# CM41x_M0 register map
Vendor: Analog Devices; Series: CM41x_M0; File version: 1p0
CPU: CM0 r0p0, little endian, MPU, FPU, 4 interrupt priority bits
Registers are 32-bit, read-write, reset 0x0 unless marked. A register's access mark holds for its fields unless they carry their own. Offsets are from the block's base; [hi:lo] are bit positions; lines under a group give offsets from that group; {n}, {i} and the like mark numbered series.

## PORTB — The General-Purpose Input/Output Port
Base 0x40008000
Same registers: PORTC 0x40009000, PORTD 0x4000A000, PORTE 0x4000B000, PORTF 0x4000C000, PORTA 0x41003000
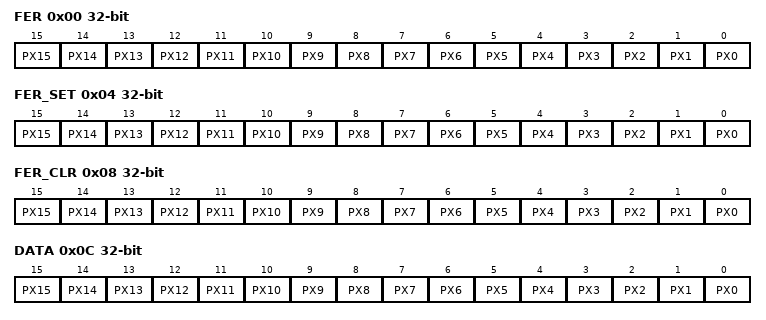
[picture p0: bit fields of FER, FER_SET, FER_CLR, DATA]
0x00 FER — Port x Function Enable Register
  [n] PX{n} (n=0..15) — Port x Bit {n} Mode
0x04 FER_SET — Port x Function Enable Set Register
  [n] PX{n} (n=0..15) — Port x Bit {n} Mode Set
0x08 FER_CLR — Port x Function Enable Clear Register
  [n] PX{n} (n=0..15) — Port x Bit {n} Mode Clear
0x0C DATA — Port x GPIO Data Register
  [n] PX{n} (n=0..15) — Port x Bit {n} Data
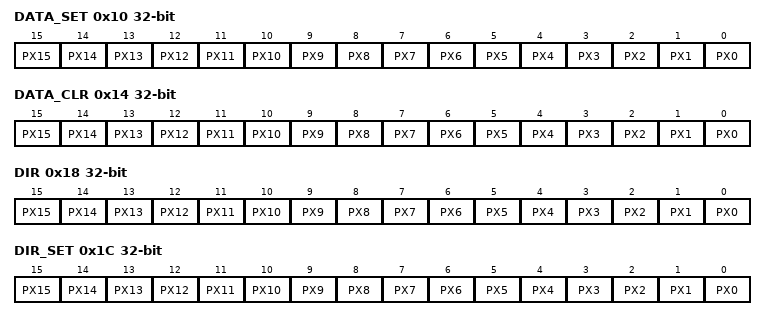
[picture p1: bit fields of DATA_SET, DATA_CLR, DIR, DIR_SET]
0x10 DATA_SET — Port x GPIO Data Set Register
  [n] PX{n} (n=0..15) — Port x Bit {n} Data Set
0x14 DATA_CLR — Port x GPIO Data Clear Register
  [n] PX{n} (n=0..15) — Port x Bit {n} Data Clear
0x18 DIR — Port x GPIO Direction Register
  [n] PX{n} (n=0..15) — Port x Bit {n} Direction
0x1C DIR_SET — Port x GPIO Direction Set Register
  [n] PX{n} (n=0..15) — Port x Bit {n} Direction Set
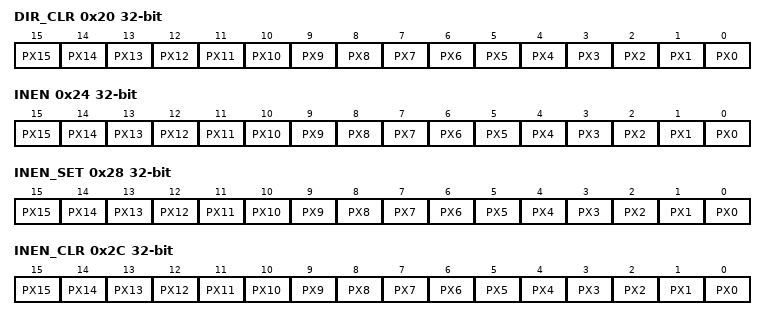
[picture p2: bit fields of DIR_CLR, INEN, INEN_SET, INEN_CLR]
0x20 DIR_CLR — Port x GPIO Direction Clear Register
  [n] PX{n} (n=0..15) — Port x Bit {n} Direction Clear
0x24 INEN — Port x GPIO Input Enable Register
  [n] PX{n} (n=0..15) — Port x Bit {n} Input Enable
0x28 INEN_SET — Port x GPIO Input Enable Set Register
  [n] PX{n} (n=0..15) — Port x Bit {n} Input Enable Set
0x2C INEN_CLR — Port x GPIO Input Enable Clear Register
  [n] PX{n} (n=0..15) — Port x Bit {n} Input Enable Clear
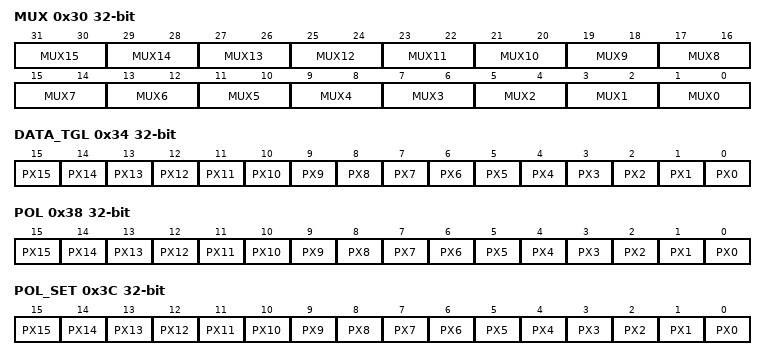
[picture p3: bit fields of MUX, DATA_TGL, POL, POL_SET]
0x30 MUX — Port x Multiplexer Control Register
  [2n+1:2n] MUX{n} range 0x00000000..0x00000003 (n=0..15) — Mux for Port x Bit {n}
0x34 DATA_TGL — Port x GPIO Output Toggle Register
  [n] PX{n} (n=0..15) — Port x Bit {n} Toggle
0x38 POL — Port x GPIO Polarity Invert Register
  [n] PX{n} (n=0..15) — Port x Bit {n} Polarity Invert
0x3C POL_SET — Port x GPIO Polarity Invert Set Register
  [n] PX{n} (n=0..15) — Port x Bit {n} Polarity Invert Set
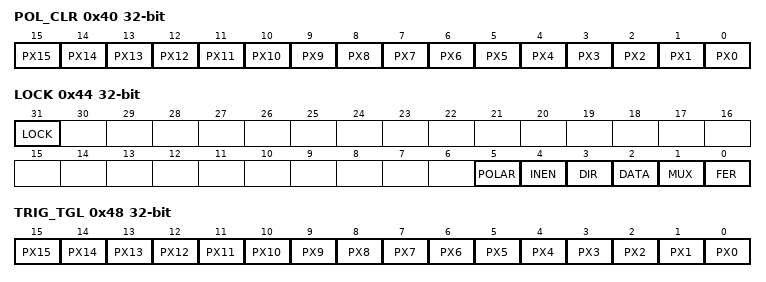
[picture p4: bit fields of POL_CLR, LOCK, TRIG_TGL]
0x40 POL_CLR — Port x GPIO Polarity Invert Clear Register
  [n] PX{n} (n=0..15) — Port x Bit {n} Polarity Invert Clear
0x44 LOCK — Port x GPIO Lock Register
  [31] LOCK
  [5] POLAR — Polarity Lock
  [4] INEN — Input Enable Lock
  [3] DIR — Direction Lock
  [2] DATA — Data, TGL Lock
  [1] MUX — Function Multiplexer Lock
  [0] FER — Function Enable Lock
0x48 TRIG_TGL — Port x GPIO Trigger Toggle Register
  [n] PX{n} range 0x00000000..0x00000001 (n=0..15) — PX{n} Data Toggle on Trigger

## LBA0 — Logic Block Array
Base 0x4000F000
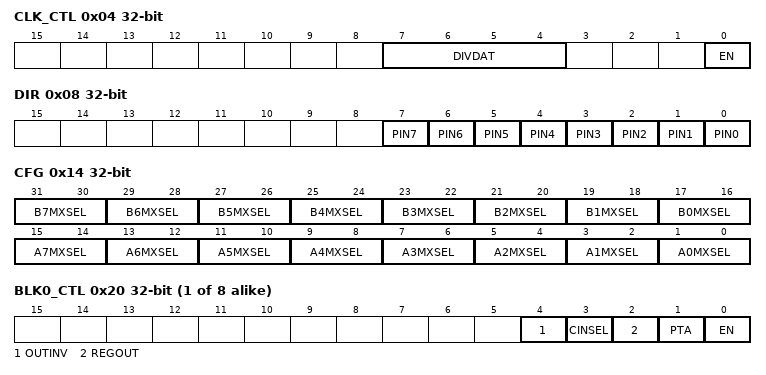
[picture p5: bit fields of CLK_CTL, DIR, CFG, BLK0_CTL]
0x04 CLK_CTL — Logic Block Array Clock Divisor Register
  [7:4] DIVDAT range 0x00000000..0x0000000F — Divisor for LBA_CLK Output
  [0] EN range 0x00000000..0x00000001 — Clock Divisor Enable
0x08 DIR — Logic Block Array Pin Direction Register
  [n] PIN{n} range 0x00000000..0x00000001 (n=0..7) — Output Enable for PIN{n}
0x0C DIN — Logic Block Array Data Input Register
  [7:0] DATA range 0x00000000..0x000000FF — Data Input Field
0x10 DOUT — Logic Block Array Data Output Register
  [7:0] DATA ro — Registered Data Output
0x14 CFG — Logic Block Array Configuration Register
  [2n+17:2n+16] B{n}MXSEL range 0x00000000..0x00000003 (n=0..7) — B{n} Multiplexer Select
  [2n+1:2n] A{n}MXSEL range 0x00000000..0x00000003 (n=0..7) — A{n} Multiplexer Select
0x18 SYNC_CTL — Logic Block Array GPIO Input Synchronization Control Register
  [7:0] SYNCIN range 0x00000000..0x000000FF — Synchronizer Select for Each GPIO Input
{0x20+4i} BLK{i}_CTL (i=0..7) — Logic Block Control Register
  [4] OUTINV range 0x00000000..0x00000001 — Invert Logic Block Output
  [3] CINSEL range 0x00000000..0x00000001 — Cascade Input Select
  [2] REGOUT range 0x00000000..0x00000001 — Registered Output Mode Select
  [1] PTA range 0x00000000..0x00000001 — Product Term Array Mode
  [0] EN range 0x00000000..0x00000001 — Enable
{0x100+0x20*i} BLK[{i}] (i=0..7) group — BLK block
  0x00 FN0 — Logic Block Function 0 Register
    [31:0] DAT range 0x00000000..0xFFFFFFFF — Look-up Table or Product Term Function Data
  0x04 FN1 — Logic Block Function 1 Register
    [31:0] DAT range 0x00000000..0xFFFFFFFF — Look-up table or Product Term Function Data
  0x08 FN2 — Logic Block Function 2 Register
    [31:0] DAT range 0x00000000..0xFFFFFFFF — Look-up Table or Product Term Array Data
  {0x0+4j} FN{j} (j=3..7) — Logic Block Function {j} Register
    [31:0] DAT range 0x00000000..0xFFFFFFFF — Look-up Table or Product Term Array Function Data
